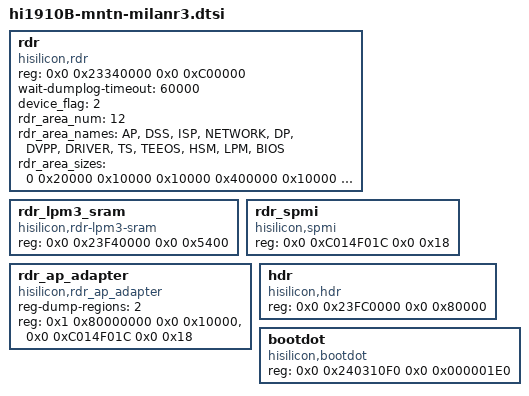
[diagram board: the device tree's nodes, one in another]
/*
 * Hisilicon Ltd. Davinci SoC
 */

	rdr {
		compatible = "hisilicon,rdr";
		reg = <0x0 0x23340000 0x0 0xC00000>;/*rdr_base_addr*/
		wait-dumplog-timeout = <60000>;
		device_flag = <2>;/*0:chip 1:fpga 2:esl*/
		rdr_area_num = <12>;
		rdr_area_names = "AP", "DSS", "ISP", "NETWORK", "DP", "DVPP", "DRIVER", "TS", "TEEOS", "HSM", "LPM", "BIOS";
		rdr_area_sizes = <0 0x20000 0x10000 0x10000 0x400000 0x10000 0x20000 0x100000 0x20000 0x40000 0x50000 0x50000>;
		status = "ok";
	};

	rdr_lpm3_sram {
		compatible = "hisilicon,rdr-lpm3-sram";
		reg = <0x0 0x23F40000 0x0 0x5400>;/*lpm3_sram_base_addr*/
		status = "ok";
	};

	rdr_spmi {
		compatible = "hisilicon,spmi";
		reg = <0x0 0xC014F01C 0x0 0x18>;/*pmu_base_addr*/
		status = "ok";
	};

	rdr_ap_adapter {
		compatible = "hisilicon,rdr_ap_adapter";
		reg-dump-regions = <2>; /*NOTE:should be less than 10*/
		reg-names = "sctrl", "pmu";
		reg = <0x1 0x80000000 0x0 0x10000>,
			<0x0 0xC014F01C 0x0 0x18>;
		status = "ok";
	};

        hdr {
		compatible = "hisilicon,hdr";
		reg = <0x0 0x23FC0000 0x0 0x80000>;
		status = "ok";
	};

        bootdot {
                compatible = "hisilicon,bootdot";
                reg = <0x0 0x240310F0 0x0 0x000001E0>;
                status = "ok";
        };
